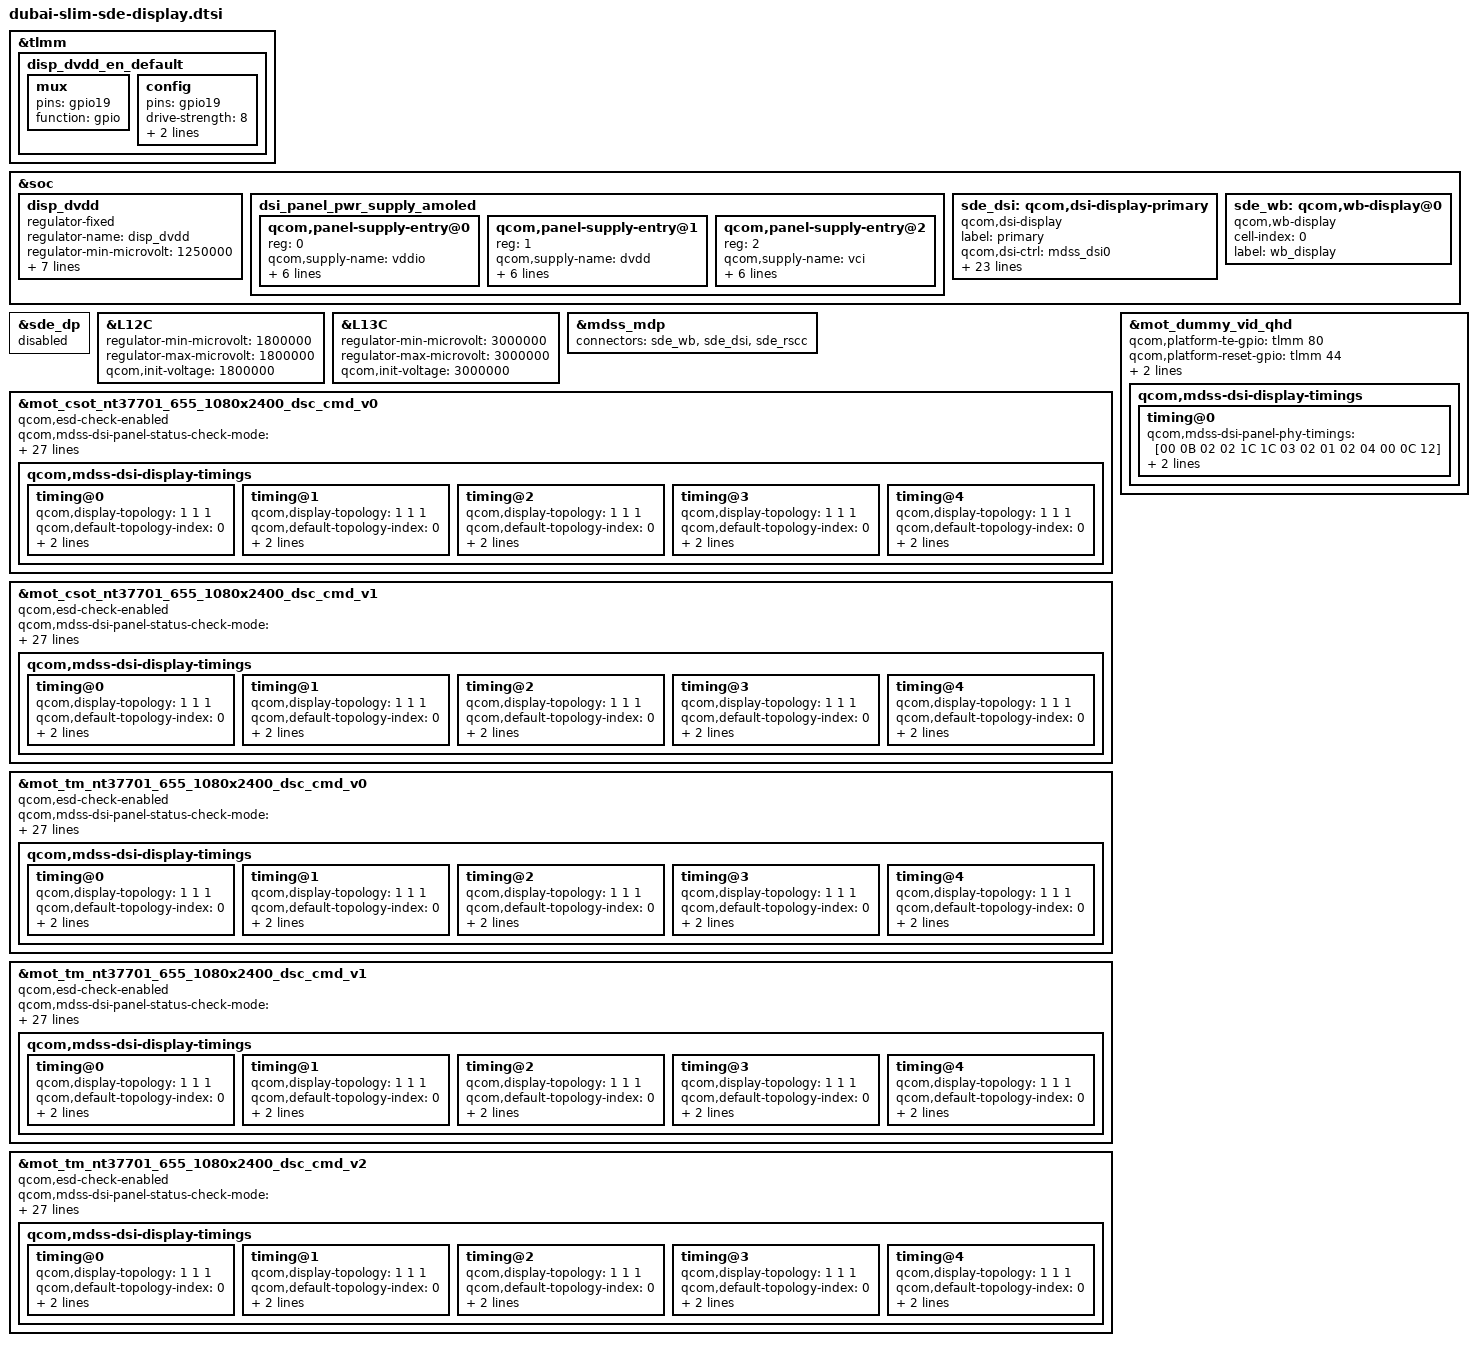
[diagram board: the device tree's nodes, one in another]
#include "dsi-panel-mot-csot-nt37701-655-1080x2400-dsc-cmd-common.dtsi"
#include "dsi-panel-mot-csot-nt37701-655-1080x2400-dsc-cmd-common-v1.dtsi"
#include "dsi-panel-mot-tianma-nt37701-655-1080x2400-dsc-cmd-common.dtsi"
#include "dsi-panel-mot-tianma-nt37701-655-1080x2400-dsc-cmd-common-v1.dtsi"
#include "dsi-panel-mot-tianma-nt37701-655-1080x2400-dsc-cmd-common-v2.dtsi"
#include "dsi-panel-mot-dummy-qhd-video.dtsi"
#include <dt-bindings/clock/mdss-5nm-pll-clk.h>
#include <dt-bindings/clock/qcom,dispcc-yupik.h>


&tlmm {
	disp_dvdd_en_default: disp_dvdd_en_default {
		mux {
			pins = "gpio19";
			function = "gpio";
		};

		config {
			pins = "gpio19";
			drive-strength = <8>;
			bias-disable = <0>;
			output-high;
		};
	};
};

&soc {
	disp_dvdd: disp_dvdd {
		compatible = "regulator-fixed";
		regulator-name = "disp_dvdd";
		regulator-min-microvolt = <1250000>;
		regulator-max-microvolt = <1250000>;
		vin-supply = <&S1B>;
		gpio = <&tlmm 19 0>;
		startup-delay-us = <300>;
		enable-active-high;
		regulator-boot-on;
		pinctrl-names = "default";
		pinctrl-0 = <&disp_dvdd_en_default>;
	};

	dsi_panel_pwr_supply_amoled: dsi_panel_pwr_supply_amoled {
		#address-cells = <1>;
		#size-cells = <0>;

		qcom,panel-supply-entry@0 {
			reg = <0>;
			qcom,supply-name = "vddio";
			qcom,supply-min-voltage = <1800000>;
			qcom,supply-max-voltage = <1800000>;
			qcom,supply-enable-load = <60700>;
			qcom,supply-disable-load = <80>;
		        qcom,supply-post-on-sleep = <2>;
			qcom,supply-post-off-sleep = <0>;
		};

		qcom,panel-supply-entry@1 {
			reg = <1>;
			qcom,supply-name = "dvdd";
			qcom,supply-min-voltage = <1250000>;
			qcom,supply-max-voltage = <1250000>;
			qcom,supply-enable-load = <60700>;
			qcom,supply-disable-load = <10>;
		        qcom,supply-post-on-sleep = <2>;
		        qcom,supply-post-off-sleep = <2>;
		};

		qcom,panel-supply-entry@2 {
			reg = <2>;
			qcom,supply-name = "vci";
			qcom,supply-min-voltage = <3000000>;
			qcom,supply-max-voltage = <3000000>;
			qcom,supply-enable-load = <30000>;
			qcom,supply-disable-load = <0>;
			qcom,supply-post-on-sleep = <0>;
			qcom,supply-post-off-sleep = <2>;
		};
	};

	sde_dsi: qcom,dsi-display-primary {
		compatible = "qcom,dsi-display";
		label = "primary";

		qcom,dsi-ctrl = <&mdss_dsi0>;
		qcom,dsi-phy = <&mdss_dsi_phy0>;

		qcom,mdp = <&mdss_mdp>;
		qcom,dsi-default-panel = <&mot_csot_nt37701_655_1080x2400_dsc_cmd_v0>;
	};
};

&soc {
	sde_wb: qcom,wb-display@0 {
		compatible = "qcom,wb-display";
		cell-index = <0>;
		label = "wb_display";
	};
};

&sde_dp {
	status = "disabled";
};

&sde_dsi {
	qcom,platform-mot-ext-feature-enable;
};

&sde_dsi {
	clocks = <&mdss_dsi_phy0 BYTECLK_MUX_0_CLK>,
			 <&mdss_dsi_phy0 PCLK_MUX_0_CLK>,
			 <&mdss_dsi_phy0 CPHY_BYTECLK_SRC_0_CLK>,
			 <&mdss_dsi_phy0 CPHY_PCLK_SRC_0_CLK>,
			 <&mdss_dsi_phy0 BYTECLK_SRC_0_CLK>,
			 <&mdss_dsi_phy0 PCLK_SRC_0_CLK>,
			 <&mdss_dsi_phy0 SHADOW_BYTECLK_SRC_0_CLK>,
			 <&mdss_dsi_phy0 SHADOW_PCLK_SRC_0_CLK>,
			 <&mdss_dsi_phy0 SHADOW_CPHY_BYTECLK_SRC_0_CLK>,
			 <&mdss_dsi_phy0 SHADOW_CPHY_PCLK_SRC_0_CLK>,
			/*
			 * Currently the dsi clock handles are under the dsi
			 * controller DT node. As soon as the controller probe
			 * finishes, the dispcc sync state can get called before
			 * the dsi_display probe potentially disturbing the clock
			 * votes for cont_splash use case. Hence we are no longer
			 * protected by the component model in this case against the
			 * disp cc sync state getting triggered after the dsi_ctrl
			 * probe. To protect against this incorrect sync state trigger
			 * add this dummy MDP clk vote handle to the dsi_display
			 * DT node. Since the dsi_display driver does not parse
			 * MDP clock nodes, no actual vote shall be added and this
			 * change is done just to satisfy sync state requirements.
			 */
			 <&dispcc DISP_CC_MDSS_MDP_CLK>;
	clock-names = "mux_byte_clk0", "mux_pixel_clk0",
			"cphy_byte_clk0", "cphy_pixel_clk0",
			"src_byte_clk0", "src_pixel_clk0",
			"shadow_byte_clk0", "shadow_pixel_clk0",
			"shadow_cphybyte_clk0", "shadow_cphypixel_clk0",
			"mdp_core_clk";

	pinctrl-names = "panel_active", "panel_suspend";
	pinctrl-0 = <&sde_dsi_active &sde_te_active>;
	pinctrl-1 = <&sde_dsi_suspend &sde_te_suspend>;

	qcom,platform-te-gpio = <&tlmm 80 0>;
	qcom,panel-te-source = <0>;

	vddio-supply = <&L12C>;
        dvdd-supply = <&disp_dvdd>;
        vci-supply = <&L13C>;

};

&L12C {
	regulator-min-microvolt = <1800000>;
	regulator-max-microvolt = <1800000>;
	qcom,init-voltage = <1800000>;
};

&L13C {
	regulator-min-microvolt = <3000000>;
	regulator-max-microvolt = <3000000>;
	qcom,init-voltage = <3000000>;
};

&mdss_mdp {
	connectors = <&sde_wb &sde_dsi &sde_rscc>;
};

&mot_csot_nt37701_655_1080x2400_dsc_cmd_v0 {
	qcom,esd-check-enabled;
	qcom,mdss-dsi-panel-status-check-mode = "te_chk_reg_rd";
	qcom,mdss-dsi-panel-status-command = [06 01 00 01 00 00 01 0a];
	qcom,mdss-dsi-panel-status-command-state = "dsi_lp_mode";
	qcom,mdss-dsi-panel-status-value = <0x9c>;
	qcom,mdss-dsi-panel-status-read-length = <1>;

	qcom,panel-supply-entries = <&dsi_panel_pwr_supply_amoled>;
	qcom,mdss-dsi-no-panel-on-read-support;
	qcom,mdss-dsi-bl-pmic-control-type = "bl_ctrl_dcs";
	qcom,mdss-dsi-bl-min-level = <9>;
	qcom,mdss-dsi-bl-max-level = <3514>;
	qcom,mdss-dsi-bl-default-level = <1757>;
	qcom,mdss-brightness-max-level = <3514>;
	qcom,fod-dim-lut = <
                /* brightness, alpha */
		1	251
		59	241
		110	237
		161	231
		212	227
		262	224
		313	220
		364	217
		415	214
		466	211
		516	208
		567	205
		618	203
		669	199
		720	196
		770	193
		821	191
		872	187
		923	185
		974	181
		1024	178
		1075	176
		1126	172
		1177	169
		1228	167
		1278	164
		1329	161
		1380	157
		1431	154
		1482	151
		1532	149
		1583	145
		1634	142
		1685	140
		1736	137
		1786	134
		1837	131
		1888	127
		1939	125
		1990	122
		2040	119
		2091	115
		2142	113
		2193	110
		2244	107
		2294	104
		2345	101
		2396	98
		2447	96
		2498	92
		2548	89
		2599	86
		2650	84
		2701	80
		2752	78
		2802	74
		2853	71
		2904	69
		2955	65
		3006	62
		3056	60
		3107	57
		3158	53
		3209	50
		3260	48
		3310	44
		3361	41
		3412	38
		3463	36
		3514	32
	>;
	qcom,platform-reset-gpio = <&tlmm 44 0>;
	qcom,bl-dsc-cmd-state = "dsi_hs_mode";

	qcom,mdss-dsi-panel-hdr-enabled;
	qcom,mdss-dsi-panel-hdr-color-primaries = <14950 15750 34000
	        16000 13000 35500 7000 2500>;
	qcom,mdss-dsi-panel-peak-brightness = <5000000>;
	qcom,mdss-dsi-panel-blackness-level = <100>;

	qcom,dsi-select-clocks = "mux_byte_clk0", "mux_pixel_clk0";

	qcom,mdss-dsi-display-timings {
		timing@0 {
			//qcom,mdss-dsi-panel-clockrate = <320000000>;
			qcom,display-topology = <1 1 1>;
			qcom,default-topology-index = <0>;
			qcom,mdss-dsi-panel-phy-timings = [00 0D 03 03 10 1D 04
							03 02 02 04 00 0C 08];
		};
		timing@1 {
			//qcom,mdss-dsi-panel-clockrate = <400000000>;
			qcom,display-topology = <1 1 1>;
			qcom,default-topology-index = <0>;
			qcom,mdss-dsi-panel-phy-timings = [00 10 03 03 11 1E 04
							04 03 02 04 00 0E 08];
		};
		timing@2 {
			//qcom,mdss-dsi-panel-clockrate = <601000000>;
			qcom,display-topology = <1 1 1>;
			qcom,default-topology-index = <0>;
			qcom,mdss-dsi-panel-phy-timings = [00 16 05 05 14 1F 06
							06 06 02 04 00 13 0A];
		};
		timing@3 {
			//qcom,mdss-dsi-panel-clockrate = <801000000>;
			qcom,display-topology = <1 1 1>;
			qcom,default-topology-index = <0>;
			qcom,mdss-dsi-panel-phy-timings = [00 1C 07 07 17 15 07
							07 08 02 04 00 18 0C];
		};
		timing@4 {
			//qcom,mdss-dsi-panel-clockrate = <961000000>;
			qcom,display-topology = <1 1 1>;
			qcom,default-topology-index = <0>;
			qcom,mdss-dsi-panel-phy-timings = [00 21 08 08 19 17 08
							08 09 02 04 00 1C 0D];
		};
	};
};

&mot_csot_nt37701_655_1080x2400_dsc_cmd_v1 {
	qcom,esd-check-enabled;
	qcom,mdss-dsi-panel-status-check-mode = "te_chk_reg_rd";
	qcom,mdss-dsi-panel-status-command = [06 01 00 01 00 00 01 0a];
	qcom,mdss-dsi-panel-status-command-state = "dsi_lp_mode";
	qcom,mdss-dsi-panel-status-value = <0x9c>;
	qcom,mdss-dsi-panel-status-read-length = <1>;

	qcom,panel-supply-entries = <&dsi_panel_pwr_supply_amoled>;
	qcom,mdss-dsi-no-panel-on-read-support;
	qcom,mdss-dsi-bl-pmic-control-type = "bl_ctrl_dcs";
	qcom,mdss-dsi-bl-min-level = <9>;
	qcom,mdss-dsi-bl-max-level = <3514>;
	qcom,mdss-dsi-bl-default-level = <1757>;
	qcom,mdss-brightness-max-level = <3514>;
	qcom,fod-dim-lut = <
                /* brightness, alpha */
		1	251
		59	241
		110	237
		161	231
		212	227
		262	224
		313	220
		364	217
		415	214
		466	211
		516	208
		567	205
		618	203
		669	199
		720	196
		770	193
		821	191
		872	187
		923	185
		974	181
		1024	178
		1075	176
		1126	172
		1177	169
		1228	167
		1278	164
		1329	161
		1380	157
		1431	154
		1482	151
		1532	149
		1583	145
		1634	142
		1685	140
		1736	137
		1786	134
		1837	131
		1888	127
		1939	125
		1990	122
		2040	119
		2091	115
		2142	113
		2193	110
		2244	107
		2294	104
		2345	101
		2396	98
		2447	96
		2498	92
		2548	89
		2599	86
		2650	84
		2701	80
		2752	78
		2802	74
		2853	71
		2904	69
		2955	65
		3006	62
		3056	60
		3107	57
		3158	53
		3209	50
		3260	48
		3310	44
		3361	41
		3412	38
		3463	36
		3514	32
	>;

	qcom,platform-reset-gpio = <&tlmm 44 0>;
	qcom,bl-dsc-cmd-state = "dsi_hs_mode";

	qcom,mdss-dsi-panel-hdr-enabled;
	qcom,mdss-dsi-panel-hdr-color-primaries = <14950 15750 34000
	        16000 13000 35500 7000 2500>;
	qcom,mdss-dsi-panel-peak-brightness = <5000000>;
	qcom,mdss-dsi-panel-blackness-level = <100>;

	qcom,dsi-select-clocks = "mux_byte_clk0", "mux_pixel_clk0";

	qcom,mdss-dsi-display-timings {
		timing@0 {
			//qcom,mdss-dsi-panel-clockrate = <320000000>;
			qcom,display-topology = <1 1 1>;
			qcom,default-topology-index = <0>;
			qcom,mdss-dsi-panel-phy-timings = [00 0D 03 03 10 1D 04
							03 02 02 04 00 0C 08];
		};
		timing@1 {
			//qcom,mdss-dsi-panel-clockrate = <400000000>;
			qcom,display-topology = <1 1 1>;
			qcom,default-topology-index = <0>;
			qcom,mdss-dsi-panel-phy-timings = [00 10 03 03 11 1E 04
							04 03 02 04 00 0E 08];
		};
		timing@2 {
			//qcom,mdss-dsi-panel-clockrate = <601000000>;
			qcom,display-topology = <1 1 1>;
			qcom,default-topology-index = <0>;
			qcom,mdss-dsi-panel-phy-timings = [00 16 05 05 14 1F 06
							06 06 02 04 00 13 0A];
		};
		timing@3 {
			//qcom,mdss-dsi-panel-clockrate = <801000000>;
			qcom,display-topology = <1 1 1>;
			qcom,default-topology-index = <0>;
			qcom,mdss-dsi-panel-phy-timings = [00 1C 07 07 17 15 07
							07 08 02 04 00 18 0C];
		};
		timing@4 {
			//qcom,mdss-dsi-panel-clockrate = <961000000>;
			qcom,display-topology = <1 1 1>;
			qcom,default-topology-index = <0>;
			qcom,mdss-dsi-panel-phy-timings = [00 21 08 08 19 17 08
							08 09 02 04 00 1C 0D];
		};
	};
};

&mot_tm_nt37701_655_1080x2400_dsc_cmd_v0 {
	qcom,esd-check-enabled;
	qcom,mdss-dsi-panel-status-check-mode = "te_chk_reg_rd";
	qcom,mdss-dsi-panel-status-command = [06 01 00 01 00 00 01 0a];
	qcom,mdss-dsi-panel-status-command-state = "dsi_lp_mode";
	qcom,mdss-dsi-panel-status-value = <0x9c>;
	qcom,mdss-dsi-panel-status-read-length = <1>;

	qcom,panel-supply-entries = <&dsi_panel_pwr_supply_amoled>;
	qcom,mdss-dsi-no-panel-on-read-support;
	qcom,mdss-dsi-bl-pmic-control-type = "bl_ctrl_dcs";
	qcom,mdss-dsi-bl-min-level = <9>;
	qcom,mdss-dsi-bl-max-level = <3514>;
	qcom,mdss-dsi-bl-default-level = <1757>;
	qcom,mdss-brightness-max-level = <3514>;
	qcom,fod-dim-lut = <
			/* brightness, alpha */
		1	251
		59	241
		110	237
		161	231
		212	227
		262	224
		313	220
		364	217
		415	214
		466	211
		516	208
		567	205
		618	203
		669	199
		720	196
		770	193
		821	191
		872	187
		923	185
		974	181
		1024	178
		1075	176
		1126	172
		1177	169
		1228	167
		1278	164
		1329	161
		1380	157
		1431	154
		1482	151
		1532	149
		1583	145
		1634	142
		1685	140
		1736	137
		1786	134
		1837	131
		1888	127
		1939	125
		1990	122
		2040	119
		2091	115
		2142	113
		2193	110
		2244	107
		2294	104
		2345	101
		2396	98
		2447	96
		2498	92
		2548	89
		2599	86
		2650	84
		2701	80
		2752	78
		2802	74
		2853	71
		2904	69
		2955	65
		3006	62
		3056	60
		3107	57
		3158	53
		3209	50
		3260	48
		3310	44
		3361	41
		3412	38
		3463	36
		3514	32
	>;
	qcom,platform-reset-gpio = <&tlmm 44 0>;
	qcom,bl-dsc-cmd-state = "dsi_hs_mode";

	qcom,mdss-dsi-panel-hdr-enabled;
	qcom,mdss-dsi-panel-hdr-color-primaries = <14950 15750 34000
	        16000 13000 35500 7000 2500>;
	qcom,mdss-dsi-panel-peak-brightness = <5000000>;
	qcom,mdss-dsi-panel-blackness-level = <100>;

	qcom,dsi-select-clocks = "mux_byte_clk0", "mux_pixel_clk0";

	qcom,mdss-dsi-display-timings {
		timing@0 {
			//qcom,mdss-dsi-panel-clockrate = <320000000>;
			qcom,display-topology = <1 1 1>;
			qcom,default-topology-index = <0>;
			qcom,mdss-dsi-panel-phy-timings = [00 0D 03 03 10 1D 04
							03 02 02 04 00 0C 08];
		};
		timing@1 {
			//qcom,mdss-dsi-panel-clockrate = <400000000>;
			qcom,display-topology = <1 1 1>;
			qcom,default-topology-index = <0>;
			qcom,mdss-dsi-panel-phy-timings = [00 10 03 03 11 1E 04
							04 03 02 04 00 0E 08];
		};
		timing@2 {
			//qcom,mdss-dsi-panel-clockrate = <601000000>;
			qcom,display-topology = <1 1 1>;
			qcom,default-topology-index = <0>;
			qcom,mdss-dsi-panel-phy-timings = [00 16 05 05 14 1F 06
							06 06 02 04 00 13 0A];
		};
		timing@3 {
			//qcom,mdss-dsi-panel-clockrate = <801000000>;
			qcom,display-topology = <1 1 1>;
			qcom,default-topology-index = <0>;
			qcom,mdss-dsi-panel-phy-timings = [00 1C 07 07 17 15 07
							07 08 02 04 00 18 0C];
		};
		timing@4 {
			//qcom,mdss-dsi-panel-clockrate = <961000000>;
			qcom,display-topology = <1 1 1>;
			qcom,default-topology-index = <0>;
			qcom,mdss-dsi-panel-phy-timings = [00 21 08 08 19 17 08
							08 09 02 04 00 1C 0D];
		};
	};
};

&mot_tm_nt37701_655_1080x2400_dsc_cmd_v1 {
	qcom,esd-check-enabled;
	qcom,mdss-dsi-panel-status-check-mode = "te_chk_reg_rd";
	qcom,mdss-dsi-panel-status-command = [06 01 00 01 00 00 01 0a];
	qcom,mdss-dsi-panel-status-command-state = "dsi_lp_mode";
	qcom,mdss-dsi-panel-status-value = <0x9c>;
	qcom,mdss-dsi-panel-status-read-length = <1>;

	qcom,panel-supply-entries = <&dsi_panel_pwr_supply_amoled>;
	qcom,mdss-dsi-no-panel-on-read-support;
	qcom,mdss-dsi-bl-pmic-control-type = "bl_ctrl_dcs";
	qcom,mdss-dsi-bl-min-level = <9>;
	qcom,mdss-dsi-bl-max-level = <3514>;
	qcom,mdss-dsi-bl-default-level = <1757>;
	qcom,mdss-brightness-max-level = <3514>;
	qcom,fod-dim-lut = <
			/* brightness, alpha */
		1	251
		59	241
		110	237
		161	231
		212	227
		262	224
		313	220
		364	217
		415	214
		466	211
		516	208
		567	205
		618	203
		669	199
		720	196
		770	193
		821	191
		872	187
		923	185
		974	181
		1024	178
		1075	176
		1126	172
		1177	169
		1228	167
		1278	164
		1329	161
		1380	157
		1431	154
		1482	151
		1532	149
		1583	145
		1634	142
		1685	140
		1736	137
		1786	134
		1837	131
		1888	127
		1939	125
		1990	122
		2040	119
		2091	115
		2142	113
		2193	110
		2244	107
		2294	104
		2345	101
		2396	98
		2447	96
		2498	92
		2548	89
		2599	86
		2650	84
		2701	80
		2752	78
		2802	74
		2853	71
		2904	69
		2955	65
		3006	62
		3056	60
		3107	57
		3158	53
		3209	50
		3260	48
		3310	44
		3361	41
		3412	38
		3463	36
		3514	32
	>;
	qcom,platform-reset-gpio = <&tlmm 44 0>;
	qcom,bl-dsc-cmd-state = "dsi_hs_mode";

	qcom,mdss-dsi-panel-hdr-enabled;
	qcom,mdss-dsi-panel-hdr-color-primaries = <14950 15750 34000
	        16000 13000 35500 7000 2500>;
	qcom,mdss-dsi-panel-peak-brightness = <5000000>;
	qcom,mdss-dsi-panel-blackness-level = <100>;

	qcom,dsi-select-clocks = "mux_byte_clk0", "mux_pixel_clk0";

	qcom,mdss-dsi-display-timings {
		timing@0 {
			//qcom,mdss-dsi-panel-clockrate = <320000000>;
			qcom,display-topology = <1 1 1>;
			qcom,default-topology-index = <0>;
			qcom,mdss-dsi-panel-phy-timings = [00 0D 03 03 10 1D 04
							03 02 02 04 00 0C 08];
		};
		timing@1 {
			//qcom,mdss-dsi-panel-clockrate = <400000000>;
			qcom,display-topology = <1 1 1>;
			qcom,default-topology-index = <0>;
			qcom,mdss-dsi-panel-phy-timings = [00 10 03 03 11 1E 04
							04 03 02 04 00 0E 08];
		};
		timing@2 {
			//qcom,mdss-dsi-panel-clockrate = <601000000>;
			qcom,display-topology = <1 1 1>;
			qcom,default-topology-index = <0>;
			qcom,mdss-dsi-panel-phy-timings = [00 16 05 05 14 1F 06
							06 06 02 04 00 13 0A];
		};
		timing@3 {
			//qcom,mdss-dsi-panel-clockrate = <801000000>;
			qcom,display-topology = <1 1 1>;
			qcom,default-topology-index = <0>;
			qcom,mdss-dsi-panel-phy-timings = [00 1C 07 07 17 15 07
							07 08 02 04 00 18 0C];
		};
		timing@4 {
			//qcom,mdss-dsi-panel-clockrate = <961000000>;
			qcom,display-topology = <1 1 1>;
			qcom,default-topology-index = <0>;
			qcom,mdss-dsi-panel-phy-timings = [00 21 08 08 19 17 08
							08 09 02 04 00 1C 0D];
		};
	};
};

&mot_tm_nt37701_655_1080x2400_dsc_cmd_v2 {
	qcom,esd-check-enabled;
	qcom,mdss-dsi-panel-status-check-mode = "te_chk_reg_rd";
	qcom,mdss-dsi-panel-status-command = [06 01 00 01 00 00 01 0a];
	qcom,mdss-dsi-panel-status-command-state = "dsi_lp_mode";
	qcom,mdss-dsi-panel-status-value = <0x9c>;
	qcom,mdss-dsi-panel-status-read-length = <1>;

	qcom,panel-supply-entries = <&dsi_panel_pwr_supply_amoled>;
	qcom,mdss-dsi-no-panel-on-read-support;
	qcom,mdss-dsi-bl-pmic-control-type = "bl_ctrl_dcs";
	qcom,mdss-dsi-bl-min-level = <9>;
	qcom,mdss-dsi-bl-max-level = <3514>;
	qcom,mdss-dsi-bl-default-level = <1757>;
	qcom,mdss-brightness-max-level = <3514>;
	qcom,fod-dim-lut = <
			/* brightness, alpha */
		1	251
		51	242
		102	237
		153	232
		204	227
		255	224
		306	220
		357	218
		408	214
		459	211
		510	208
		561	205
		611	203
		662	200
		713	196
		764	193
		815	191
		866	188
		917	185
		968	182
		1019	179
		1070	176
		1121	172
		1172	169
		1222	167
		1273	164
		1324	162
		1375	158
		1426	154
		1477	152
		1528	149
		1579	145
		1630	143
		1681	140
		1732	137
		1782	135
		1833	131
		1884	127
		1935	126
		1986	122
		2037	119
		2088	116
		2139	113
		2190	110
		2241	107
		2292	104
		2343	101
		2393	98
		2444	96
		2495	92
		2546	89
		2597	86
		2648	84
		2699	80
		2750	78
		2801	74
		2852	71
		2903	69
		2953	65
		3004	62
		3055	60
		3106	57
		3157	53
		3208	51
		3259	48
		3310	44
		3361	41
		3412	38
		3463	36
		3514	32
	>;
	qcom,platform-reset-gpio = <&tlmm 44 0>;
	qcom,bl-dsc-cmd-state = "dsi_hs_mode";

	qcom,mdss-dsi-panel-hdr-enabled;
	qcom,mdss-dsi-panel-hdr-color-primaries = <14950 15750 34000
	        16000 13000 35500 7000 2500>;
	qcom,mdss-dsi-panel-peak-brightness = <5000000>;
	qcom,mdss-dsi-panel-blackness-level = <100>;

	qcom,dsi-select-clocks = "mux_byte_clk0", "mux_pixel_clk0";

	qcom,mdss-dsi-display-timings {
		timing@0 {
			//qcom,mdss-dsi-panel-clockrate = <320000000>;
			qcom,display-topology = <1 1 1>;
			qcom,default-topology-index = <0>;
			qcom,mdss-dsi-panel-phy-timings = [00 0D 03 03 10 1D 04
							03 02 02 04 00 0C 08];
		};
		timing@1 {
			//qcom,mdss-dsi-panel-clockrate = <400000000>;
			qcom,display-topology = <1 1 1>;
			qcom,default-topology-index = <0>;
			qcom,mdss-dsi-panel-phy-timings = [00 10 03 03 11 1E 04
							04 03 02 04 00 0E 08];
		};
		timing@2 {
			//qcom,mdss-dsi-panel-clockrate = <601000000>;
			qcom,display-topology = <1 1 1>;
			qcom,default-topology-index = <0>;
			qcom,mdss-dsi-panel-phy-timings = [00 16 05 05 14 1F 06
							06 06 02 04 00 13 0A];
		};
		timing@3 {
			//qcom,mdss-dsi-panel-clockrate = <801000000>;
			qcom,display-topology = <1 1 1>;
			qcom,default-topology-index = <0>;
			qcom,mdss-dsi-panel-phy-timings = [00 1C 07 07 17 15 07
							07 08 02 04 00 18 0C];
		};
		timing@4 {
			//qcom,mdss-dsi-panel-clockrate = <961000000>;
			qcom,display-topology = <1 1 1>;
			qcom,default-topology-index = <0>;
			qcom,mdss-dsi-panel-phy-timings = [00 21 08 08 19 17 08
							08 09 02 04 00 1C 0D];
		};
	};
};

&mot_dummy_vid_qhd {
	qcom,platform-te-gpio = <&tlmm 80 0>;
	qcom,platform-reset-gpio = <&tlmm 44 0>;

	qcom,dsi-select-clocks = "mux_byte_clk0", "mux_pixel_clk0";
	qcom,mdss-dsi-display-timings {
		timing@0 {
			qcom,mdss-dsi-panel-phy-timings = [00 0B 02 02 1C 1C 03
							02 01 02 04 00 0C 12];
			qcom,display-topology = <1 0 1>;
			qcom,default-topology-index = <0>;
		};
	};
};

